# TC37X register map
File version: 1.0.0
CPU: CM4 r0p1, little endian, MPU, FPU, VTOR, 3 interrupt priority bits
Registers are 16-bit, read-write, reset 0x0 unless marked. A register's access mark holds for its fields unless they carry their own. Offsets are from the block's base; [hi:lo] are bit positions; {n}, {i} and the like mark numbered series; 'fields as' and 'values as' point back to an identical list.

## MTU — ce_mtu
Base 0xF0060000
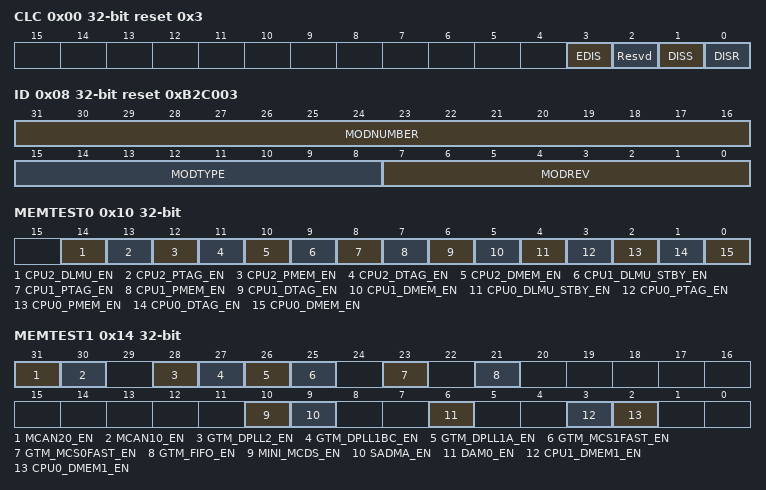
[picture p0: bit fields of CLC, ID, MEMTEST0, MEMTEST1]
0x00 CLC 32-bit reset 0x3 — Clock Control Register
  [3] EDIS — Sleep Mode Enable Control - EDIS
  [2] Resvd ro — Resvd - Resvd
  [1] DISS ro — Module Disable Status Bit - DISS
  [0] DISR — Module Disable Request Bit - DISR
0x08 ID 32-bit ro reset 0xB2C003 — Identification Register
  [31:16] MODNUMBER — Module Number - MODNUMBER
  [15:8] MODTYPE — Module Type - MODTYPE
  [7:0] MODREV — Module Revision Number - MODREV
0x10 MEMTEST0 32-bit — Memory MBIST Enable Register 0
  [14] CPU2_DLMU_EN — CPU2 DLMU memory SSH instance Enable - CPU2_DLMU_EN
  [13] CPU2_PTAG_EN — CPU2 PTAG SSH instance Enable - CPU2_PTAG_EN
  [12] CPU2_PMEM_EN — CPU2 PMEM SSH instance Enable - CPU2_PMEM_EN
  [11] CPU2_DTAG_EN — CPU2 DTAG SSH instance Enable - CPU2_DTAG_EN
  [10] CPU2_DMEM_EN — CPU2 DMEM SSH instance Enable - CPU2_DMEM_EN
  [9] CPU1_DLMU_STBY_EN — CPU1 STANDBY DLMU SSH instance Enable - CPU1_DLMU_STBY_EN
  [8] CPU1_PTAG_EN — CPU1 PTAG SSH instance Enable - CPU1_PTAG_EN
  [7] CPU1_PMEM_EN — CPU1 PMEM SSH instance Enable - CPU1_PMEM_EN
  [6] CPU1_DTAG_EN — CPU1 DTAG SSH instance Enable - CPU1_DTAG_EN
  [5] CPU1_DMEM_EN — CPU1 DMEM SSH instance Enable - CPU1_DMEM_EN
  [4] CPU0_DLMU_STBY_EN — CPU0 STANDBY DLMU SSH instance Enable - CPU0_DLMU_STBY_EN
  [3] CPU0_PTAG_EN — CPU0 PTAG SSH instance Enable - CPU0_PTAG_EN
  [2] CPU0_PMEM_EN — CPU0 PMEM SSH instance Enable - CPU0_PMEM_EN
  [1] CPU0_DTAG_EN — CPU0 DTAG SSH instance Enable - CPU0_DTAG_EN
  [0] CPU0_DMEM_EN — CPU0 DMEM SSH instance Enable - CPU0_DMEM_EN
0x14 MEMTEST1 32-bit — Memory MBIST Enable Register 1
  [31] MCAN20_EN — MCAN20 memory SSH instance Enable - MCAN20_EN
  [30] MCAN10_EN — MCAN10 memory SSH instance Enable - MCAN10_EN
  [28] GTM_DPLL2_EN — GTM DPLL2 memory SSH instance Enable - GTM_DPLL2_EN
  [27] GTM_DPLL1BC_EN — GTM DPLL1BC memory SSH instance Enable - GTM_DPLL1BC_EN
  [26] GTM_DPLL1A_EN — GTM DPLL1A memory SSH instance Enable - GTM_DPLL1A_EN
  [25] GTM_MCS1FAST_EN — GTM MCS1 FAST memory SSH instance Enable - GTM_MCS1FAST_EN
  [23] GTM_MCS0FAST_EN — GTM MCS0 FAST memory SSH instance Enable - GTM_MCS0FAST_EN
  [21] GTM_FIFO_EN — GTM FIFO memory SSH instance Enable - GTM_FIFO_EN
  [10] MINI_MCDS_EN — MINI MCDS memory SSH instance Enable - MINI_MCDS_EN
  [9] SADMA_EN — Safety DMA SSH instance Enable - SADMA_EN
  [6] DAM0_EN — DAM0 SSH instance Enable - DAM0_EN
  [3] CPU1_DMEM1_EN — CPU1 DMEM1 SSH instance Enable - CPU1_DMEM1_EN
  [2] CPU0_DMEM1_EN — CPU0 DMEM1 SSH instance Enable - CPU0_DMEM1_EN
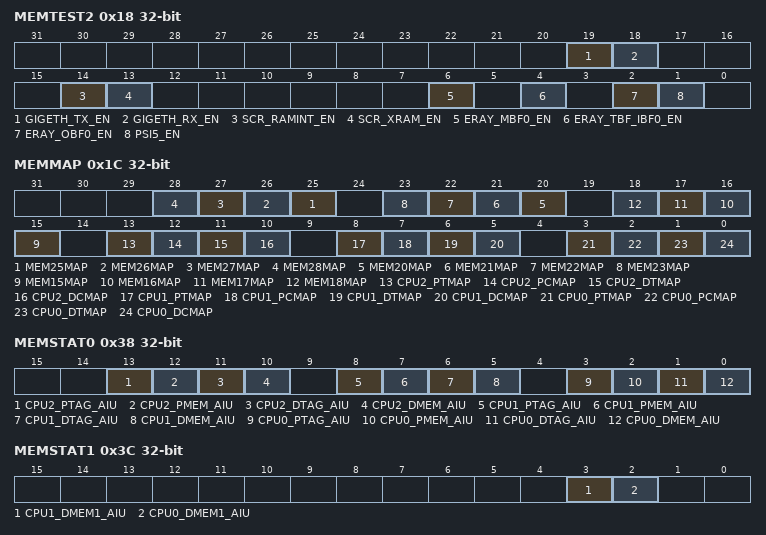
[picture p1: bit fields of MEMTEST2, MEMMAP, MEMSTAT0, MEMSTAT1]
0x18 MEMTEST2 32-bit — Memory MBIST Enable Register 2
  [19] GIGETH_TX_EN — Gigabit Ethernet TX SSH instance Enable - GIGETH_TX_EN
  [18] GIGETH_RX_EN — Gigabit Ethernet RX SSH instance Enable - GIGETH_RX_EN
  [14] SCR_RAMINT_EN — SCR Internal RAM SSH instance Enable - SCR_RAMINT_EN
  [13] SCR_XRAM_EN — SCR XRAM SSH instance Enable - SCR_XRAM_EN
  [6] ERAY_MBF0_EN — ERAY MBF0 memory SSH instance Enable - ERAY_MBF0_EN
  [4] ERAY_TBF_IBF0_EN — ERAY TBF IBF0 memory SSH instance Enable - ERAY_TBF_IBF0_EN
  [2] ERAY_OBF0_EN — ERAY OBF0 SSH instance Enable - ERAY_OBF0_EN
  [1] PSI5_EN — PSI5 memory SSH instance Enable - PSI5_EN
0x1C MEMMAP 32-bit — Memory Mapping Enable Register
  [n] MEM{n}MAP ro (n=25..28) — MEM{n} Mapping Enable - MEM{n}MAP
  [n] MEM{n}MAP ro (n=20..23) — MEM{n} Mapping Enable - MEM{n}MAP
  [n] MEM{n}MAP ro (n=15..18) — MEM{n} Mapping Enable - MEM{n}MAP
  [13] CPU2_PTMAP ro — CPU2 PTAG Mapping - CPU2_PTMAP
  [12] CPU2_PCMAP — CPU2 PCACHE Mapping - CPU2_PCMAP
  [11] CPU2_DTMAP ro — CPU2 DTAG Mapping - CPU2_DTMAP
  [10] CPU2_DCMAP — CPU2 DCache Mapping - CPU2_DCMAP
  [8] CPU1_PTMAP ro — CPU1 PTAG Mapping - CPU1_PTMAP
  [7] CPU1_PCMAP — CPU1 PCACHE Mapping - CPU1_PCMAP
  [6] CPU1_DTMAP ro — CPU1 DTAG Mapping - CPU1_DTMAP
  [5] CPU1_DCMAP — CPU1 DCache Mapping - CPU1_DCMAP
  [3] CPU0_PTMAP ro — CPU0 PTAG Mapping - CPU0_PTMAP
  [2] CPU0_PCMAP — CPU0 PCACHE Mapping - CPU0_PCMAP
  [1] CPU0_DTMAP ro — CPU0 DTAG Mapping - CPU0_DTMAP
  [0] CPU0_DCMAP — CPU0 DCache Mapping - CPU0_DCMAP
0x38 MEMSTAT0 32-bit ro — Memory Status Register 0
  [13] CPU2_PTAG_AIU — CPU2 PTAG MBIST AutoInitialize Underway - CPU2_PTAG_AIU
  [12] CPU2_PMEM_AIU — CPU2 PMEM Partial AutoInitialize of Cache Partition Underway - CPU2_PMEM_AIU
  [11] CPU2_DTAG_AIU — CPU2 DTAG MBIST AutoInitialize Underway - CPU2_DTAG_AIU
  [10] CPU2_DMEM_AIU — CPU2 DMEM Partial AutoInitialize of Cache Partition Underway - CPU2_DMEM_AIU
  [8] CPU1_PTAG_AIU — CPU1 PTAG MBIST AutoInitialize Underway - CPU1_PTAG_AIU
  [7] CPU1_PMEM_AIU — CPU1 PMEM Partial AutoInitialize of Cache Partition Underway - CPU1_PMEM_AIU
  [6] CPU1_DTAG_AIU — CPU1 DTAG MBIST AutoInitialize Underway - CPU1_DTAG_AIU
  [5] CPU1_DMEM_AIU — CPU1 DMEM Partial AutoInitialize of Cache Partition Underway - CPU1_DMEM_AIU
  [3] CPU0_PTAG_AIU — CPU0 PTAG MBIST AutoInitialize Underway - CPU0_PTAG_AIU
  [2] CPU0_PMEM_AIU — CPU0 PMEM Partial AutoInitialize of Cache Partition Underway - CPU0_PMEM_AIU
  [1] CPU0_DTAG_AIU — CPU0 DTAG MBIST AutoInitialize Underway - CPU0_DTAG_AIU
  [0] CPU0_DMEM_AIU — CPU0 DMEM Partial AutoInitialize of Cache Partition Underway - CPU0_DMEM_AIU
0x3C MEMSTAT1 32-bit ro — Memory Status Register 1
  [3] CPU1_DMEM1_AIU — CPU1 DMEM1 Partial AutoInitialize of Cache Partition Underway - CPU1_DMEM1_AIU
  [2] CPU0_DMEM1_AIU — CPU0 DMEM1 Partial AutoInitialize of Cache Partition Underway - CPU0_DMEM1_AIU
0x40 MEMSTAT2 32-bit ro — Memory Status Register 2
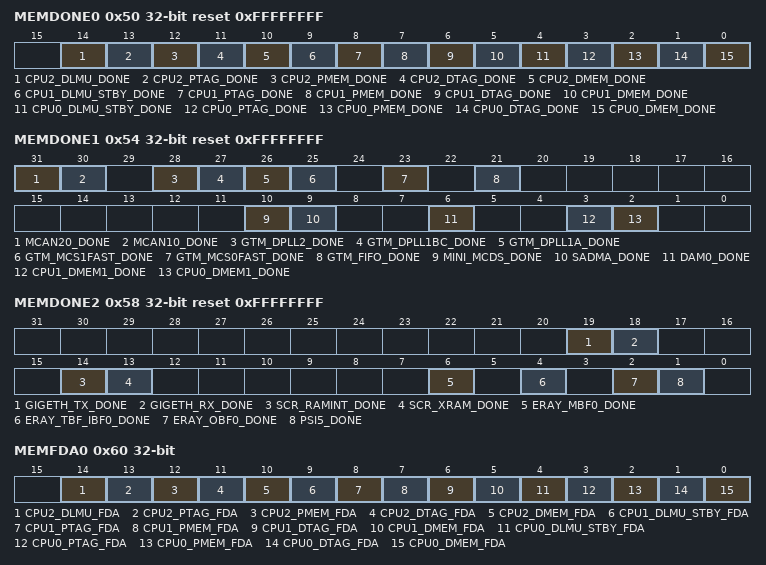
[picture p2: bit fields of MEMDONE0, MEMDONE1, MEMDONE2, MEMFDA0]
0x50 MEMDONE0 32-bit ro reset 0xFFFFFFFF — Memory Test Done Status Register 0
  [14] CPU2_DLMU_DONE — CPU2 DLMU memory Test Done Status - CPU2_DLMU_DONE
  [13] CPU2_PTAG_DONE — CPU2 PTAG Test Done Status - CPU2_PTAG_DONE
  [12] CPU2_PMEM_DONE — CPU2 PMEM Test Done Status - CPU2_PMEM_DONE
  [11] CPU2_DTAG_DONE — CPU2 DTAG Test Done Status - CPU2_DTAG_DONE
  [10] CPU2_DMEM_DONE — CPU2 DMEM Test Done Status - CPU2_DMEM_DONE
  [9] CPU1_DLMU_STBY_DONE — CPU1 STANDBY DLMU Test Done Status - CPU1_DLMU_STBY_DONE
  [8] CPU1_PTAG_DONE — CPU1 PTAG Test Done Status - CPU1_PTAG_DONE
  [7] CPU1_PMEM_DONE — CPU1 PMEM Test Done Status - CPU1_PMEM_DONE
  [6] CPU1_DTAG_DONE — CPU1 DTAG Test Done Status - CPU1_DTAG_DONE
  [5] CPU1_DMEM_DONE — CPU1 DMEM Test Done Status - CPU1_DMEM_DONE
  [4] CPU0_DLMU_STBY_DONE — CPU0 STANDBY DLMU Test Done Status - CPU0_DLMU_STBY_DONE
  [3] CPU0_PTAG_DONE — CPU0 PTAG Test Done Status - CPU0_PTAG_DONE
  [2] CPU0_PMEM_DONE — CPU0 PMEM Test Done Status - CPU0_PMEM_DONE
  [1] CPU0_DTAG_DONE — CPU0 DTAG Test Done Status - CPU0_DTAG_DONE
  [0] CPU0_DMEM_DONE — CPU0 DMEM Test Done Status - CPU0_DMEM_DONE
0x54 MEMDONE1 32-bit ro reset 0xFFFFFFFF — Memory Test Done Status Register 1
  [31] MCAN20_DONE — MCAN20 memory Test Done Status - MCAN20_DONE
  [30] MCAN10_DONE — MCAN10 memory Test Done Status - MCAN10_DONE
  [28] GTM_DPLL2_DONE — GTM DPLL2 memory Test Done Status - GTM_DPLL2_DONE
  [27] GTM_DPLL1BC_DONE — GTM DPLL1BC memory Test Done Status - GTM_DPLL1BC_DONE
  [26] GTM_DPLL1A_DONE — GTM DPLL1A memory Test Done Status - GTM_DPLL1A_DONE
  [25] GTM_MCS1FAST_DONE — GTM MCS1 FAST memory Test Done Status - GTM_MCS1FAST_DONE
  [23] GTM_MCS0FAST_DONE — GTM MCS0 FAST memory Test Done Status - GTM_MCS0FAST_DONE
  [21] GTM_FIFO_DONE — GTM FIFO memory Test Done Status - GTM_FIFO_DONE
  [10] MINI_MCDS_DONE — MINI MCDS memory Test Done Status - MINI_MCDS_DONE
  [9] SADMA_DONE — Safety DMA Test Done Status - SADMA_DONE
  [6] DAM0_DONE — DAM0 Test Done Status - DAM0_DONE
  [3] CPU1_DMEM1_DONE — CPU1 DMEM1 Test Done Status - CPU1_DMEM1_DONE
  [2] CPU0_DMEM1_DONE — CPU0 DMEM1 Test Done Status - CPU0_DMEM1_DONE
0x58 MEMDONE2 32-bit ro reset 0xFFFFFFFF — Memory Test Done Status Register 2
  [19] GIGETH_TX_DONE — Gigabit Ethernet TX memoryTest Done Status - GIGETH_TX_DONE
  [18] GIGETH_RX_DONE — Gigabit Ethernet RX memoryTest Done Status - GIGETH_RX_DONE
  [14] SCR_RAMINT_DONE — SCR Internal RAM Test Done Status - SCR_RAMINT_DONE
  [13] SCR_XRAM_DONE — SCR XRAM Test Done Status - SCR_XRAM_DONE
  [6] ERAY_MBF0_DONE — ERAY MBF0 memory Test Done Status - ERAY_MBF0_DONE
  [4] ERAY_TBF_IBF0_DONE — ERAY TBF IBF0 memory Test Done Status - ERAY_TBF_IBF0_DONE
  [2] ERAY_OBF0_DONE — ERAY OBF0 Test Done Status - ERAY_OBF0_DONE
  [1] PSI5_DONE — PSI5 memory Test Done Status - PSI5_DONE
0x60 MEMFDA0 32-bit ro — Memory Test FDA Status Register 0
  [14] CPU2_DLMU_FDA — CPU2 DLMU memory Test FDA Status - CPU2_DLMU_FDA
  [13] CPU2_PTAG_FDA — CPU2 PTAG Test FDA Status - CPU2_PTAG_FDA
  [12] CPU2_PMEM_FDA — CPU2 PMEM Test FDA Status - CPU2_PMEM_FDA
  [11] CPU2_DTAG_FDA — CPU2 DTAG Test FDA Status - CPU2_DTAG_FDA
  [10] CPU2_DMEM_FDA — CPU2 DMEM Test FDA Status - CPU2_DMEM_FDA
  [9] CPU1_DLMU_STBY_FDA — CPU1 STANDBY DLMU Test FDA Status - CPU1_DLMU_STBY_FDA
  [8] CPU1_PTAG_FDA — CPU1 PTAG Test FDA Status - CPU1_PTAG_FDA
  [7] CPU1_PMEM_FDA — CPU1 PMEM Test FDA Status - CPU1_PMEM_FDA
  [6] CPU1_DTAG_FDA — CPU1 DTAG Test FDA Status - CPU1_DTAG_FDA
  [5] CPU1_DMEM_FDA — CPU1 DMEM Test FDA Status - CPU1_DMEM_FDA
  [4] CPU0_DLMU_STBY_FDA — CPU0 STANDBY DLMU Test FDA Status - CPU0_DLMU_STBY_FDA
  [3] CPU0_PTAG_FDA — CPU0 PTAG Test FDA Status - CPU0_PTAG_FDA
  [2] CPU0_PMEM_FDA — CPU0 PMEM Test FDA Status - CPU0_PMEM_FDA
  [1] CPU0_DTAG_FDA — CPU0 DTAG Test FDA Status - CPU0_DTAG_FDA
  [0] CPU0_DMEM_FDA — CPU0 DMEM Test FDA Status - CPU0_DMEM_FDA
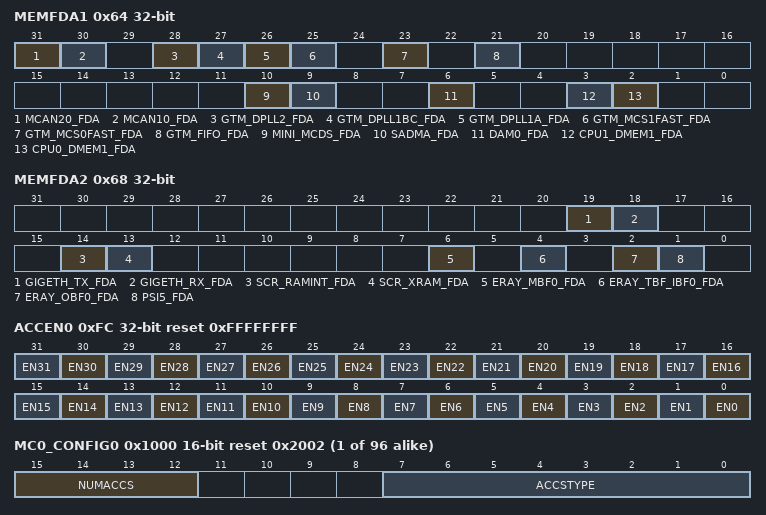
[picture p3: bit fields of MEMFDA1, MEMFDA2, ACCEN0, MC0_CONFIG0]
0x64 MEMFDA1 32-bit ro — Memory Test FDA Status Register 1
  [31] MCAN20_FDA — MCAN20 memory Test FDA Status - MCAN20_FDA
  [30] MCAN10_FDA — MCAN10 memory Test FDA Status - MCAN10_FDA
  [28] GTM_DPLL2_FDA — GTM DPLL2 memory Test FDA Status - GTM_DPLL2_FDA
  [27] GTM_DPLL1BC_FDA — GTM DPLL1BC memory Test FDA Status - GTM_DPLL1BC_FDA
  [26] GTM_DPLL1A_FDA — GTM DPLL1A memory Test FDA Status - GTM_DPLL1A_FDA
  [25] GTM_MCS1FAST_FDA — GTM MCS1 FAST memory Test FDA Status - GTM_MCS1FAST_FDA
  [23] GTM_MCS0FAST_FDA — GTM MCS0 FAST memory Test FDA Status - GTM_MCS0FAST_FDA
  [21] GTM_FIFO_FDA — GTM FIFO memory Test FDA Status - GTM_FIFO_FDA
  [10] MINI_MCDS_FDA — MINI MCDS memory Test FDA Status - MINI_MCDS_FDA
  [9] SADMA_FDA — Safety DMA Test FDA Status - SADMA_FDA
  [6] DAM0_FDA — DAM0 Test FDA Status - DAM0_FDA
  [3] CPU1_DMEM1_FDA — CPU1 DMEM1 Test FDA Status - CPU1_DMEM1_FDA
  [2] CPU0_DMEM1_FDA — CPU0 DMEM1 Test FDA Status - CPU0_DMEM1_FDA
0x68 MEMFDA2 32-bit ro — Memory Test FDA Status Register 2
  [19] GIGETH_TX_FDA — Gigabit Ethernet TX SSH memory Test FDA Status - GIGETH_TX_FDA
  [18] GIGETH_RX_FDA — Gigabit Ethernet RX memory Test FDA Status - GIGETH_RX_FDA
  [14] SCR_RAMINT_FDA — SCR Internal RAM Test FDA Status - SCR_RAMINT_FDA
  [13] SCR_XRAM_FDA — SCR XRAM Test FDA Status - SCR_XRAM_FDA
  [6] ERAY_MBF0_FDA — ERAY MBF0 memory Test FDA Status - ERAY_MBF0_FDA
  [4] ERAY_TBF_IBF0_FDA — ERAY TBF IBF0 memory Test FDA Status - ERAY_TBF_IBF0_FDA
  [2] ERAY_OBF0_FDA — ERAY OBF0 Test FDA Status - ERAY_OBF0_FDA
  [1] PSI5_FDA — PSI5 memory Test FDA Status - PSI5_FDA
0xF8 ACCEN1 32-bit ro — Access Enable Register 1
0xFC ACCEN0 32-bit reset 0xFFFFFFFF — Access Enable Register 0
  [n] EN{n} (n=0..31) — Access Enable for Master TAG ID {n} - EN{n}
{0x1000+0x100*i} MC{i}_CONFIG0 reset 0x2002 (i=0..95) — Configuration Registers
  [15:12] NUMACCS — Number of accesses per address - NUMACCS
  [7:0] ACCSTYPE — Access type - ACCSTYPE
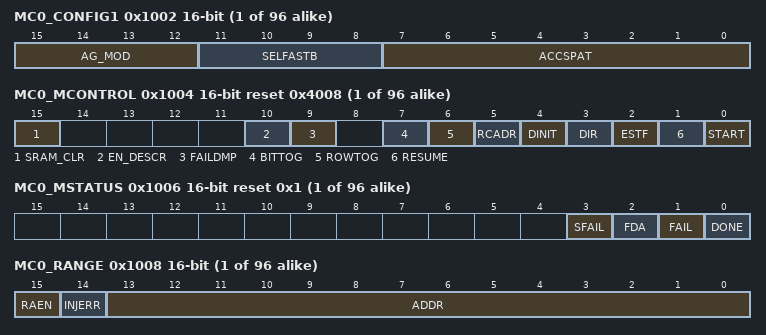
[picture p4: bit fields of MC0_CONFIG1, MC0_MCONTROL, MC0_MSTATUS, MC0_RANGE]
{0x1002+0x100*i} MC{i}_CONFIG1 (i=0..95) — Configuration Register 1
  [15:12] AG_MOD — Address Generator Mode - AG_MOD
  [11:8] SELFASTB — Select Fast Bit - SELFASTB
  [7:0] ACCSPAT — Access pattern - ACCSPAT
{0x1004+0x100*i} MC{i}_MCONTROL reset 0x4008 (i=0..95) — MBIST Control Register
  [15] SRAM_CLR — Clear the SRAM - SRAM_CLR
  [10] EN_DESCR — Enable Descrambling
  [9] FAILDMP — Fail bitmap dump - FAILDMP
  [7] BITTOG — Bit toggling - BITTOG
  [6] ROWTOG — Row toggling - ROWTOG
  [5] RCADR — Fast Row / Fast Column Addressing Scheme Select - RCADR
  [4] DINIT — Data Initialization Enable - DINIT
  [3] DIR — Direction Select - DIR
  [2] ESTF — Enable Sticky Fail Bit - ESTF
  [1] RESUME — Resume failed test - RESUME
  [0] START — START - START
{0x1006+0x100*i} MC{i}_MSTATUS ro reset 0x1 (i=0..95) — Status Register
  [3] SFAIL — Sticky Fail Bit - SFAIL
  [2] FDA — Fail Dump Available - FDA
  [1] FAIL — FAIL - FAIL
  [0] DONE — DONE - DONE
{0x1008+0x100*i} MC{i}_RANGE reset not defined (i=0..95) — Range Register, single address mode
  [15] RAEN — Range Enable - RAEN
  [14] INJERR — Inject Error - INJERR
  [13:0] ADDR — Address - ADDR
{0x100C+0x100*i} MC{i}_REVID ro reset 0x610 (i=0..95) — Revision ID Register
  [15:0] REV_ID — Revision Identifier - REV_ID
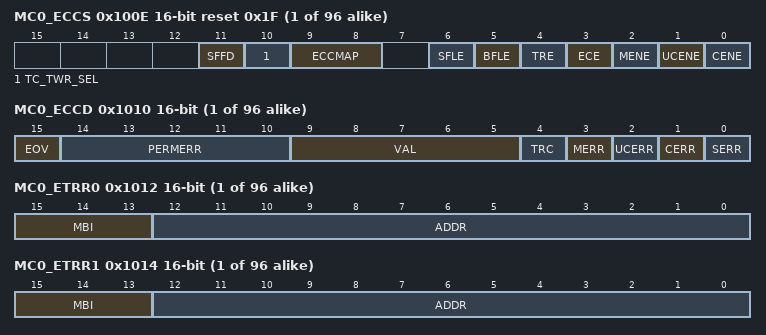
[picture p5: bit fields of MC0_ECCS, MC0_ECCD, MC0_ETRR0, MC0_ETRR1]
{0x100E+0x100*i} MC{i}_ECCS reset 0x1F (i=0..95) — ECC Safety Register
  [11] SFFD — Safety Flip-Flop Diagnostics - SFFD
  [10] TC_TWR_SEL — TriCore Tower Select - TC_TWR_SEL
  [9:8] ECCMAP — ECC Bit Mapping Mode - ECCMAP
  [6] SFLE — Signature Bit Flip Enables - SFLE
  [5] BFLE — Bit Flip Enable - BFLE
  [4] TRE — Tracking Enable - TRE
  [3] ECE — Error Correction Enable - ECE
  [2] MENE — Miscellaneous Alarm Notification Enable: MENE
  [1] UCENE — Uncorrectable Error Affecting SRAM / SSH Operation: Alarm Notification Enable - UENE
  [0] CENE — ECC Correction Event Alarm Notification Enable - CENE
{0x1010+0x100*i} MC{i}_ECCD (i=0..95) — Memory ECC Detection Register
  [15] EOV ro — Error Overflow - EOV
  [14:10] PERMERR — Permanent Error in ETRR Entry - PERMERR
  [9:5] VAL ro — Valid Bits - VAL
  [4] TRC wo — Tracking Clear - TRC
  [3] MERR — Miscellaneous Error Alarm Occured - MERR
  [2] UCERR — Uncorrectable Error Alarm Occured - UCERR
  [1] CERR — CE alarm occured - CERR
  [0] SERR — Error Detected - SERR
{0x1012+0x100*i} MC{i}_ETRR0 ro (i=0..95) — Error Tracking Register 0
  [15:13] MBI — Memory Block Index of Error(i) - MBI
  [12:0] ADDR — Address of Error(i) - ADDR
{0x1014+0x100*i} MC{i}_ETRR1 ro (i=0..95) — Error Tracking Register 1
  fields as MC0_ETRR0
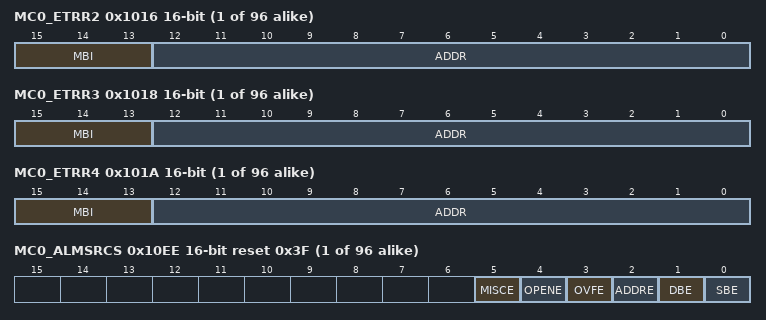
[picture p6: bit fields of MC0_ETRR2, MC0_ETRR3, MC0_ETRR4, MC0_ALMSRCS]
{0x1016+0x100*i} MC{i}_ETRR2 ro (i=0..95) — Error Tracking Register 2
  fields as MC0_ETRR0
{0x1018+0x100*i} MC{i}_ETRR3 ro (i=0..95) — Error Tracking Register 3
  fields as MC0_ETRR0
{0x101A+0x100*i} MC{i}_ETRR4 ro (i=0..95) — Error Tracking Register 4
  fields as MC0_ETRR0
{0x1060+0x100*i} MC{i}_RDBFL0 (i=0..95) — Read Data and Bit Flip Register 0
  [15:0] WDATA — Word Data - WDATA
{0x1062+0x100*i} MC{i}_RDBFL1 (i=0..95) — Read Data and Bit Flip Register 1
  [15:0] WDATA — Word Data - WDATA
{0x1064+0x100*i} MC{i}_RDBFL2 (i=0..95) — Read Data and Bit Flip Register 2
  [15:0] WDATA — Word Data - WDATA
{0x1066+0x100*i} MC{i}_RDBFL3 (i=0..95) — Read Data and Bit Flip Register 3
  [15:0] WDATA — Word Data - WDATA
{0x1068+0x100*i} MC{i}_RDBFL4 (i=0..95) — Read Data and Bit Flip Register 4
  [15:0] WDATA — Word Data - WDATA
{0x106A+0x100*i} MC{i}_RDBFL5 (i=0..95) — Read Data and Bit Flip Register 5
  [15:0] WDATA — Word Data - WDATA
{0x106C+0x100*i} MC{i}_RDBFL6 (i=0..95) — Read Data and Bit Flip Register 6
  [15:0] WDATA — Word Data - WDATA
{0x106E+0x100*i} MC{i}_RDBFL7 (i=0..95) — Read Data and Bit Flip Register 7
  [15:0] WDATA — Word Data - WDATA
{0x1070+0x100*i} MC{i}_RDBFL8 (i=0..95) — Read Data and Bit Flip Register 8
  [15:0] WDATA — Word Data - WDATA
{0x1072+0x100*i} MC{i}_RDBFL9 (i=0..95) — Read Data and Bit Flip Register 9
  [15:0] WDATA — Word Data - WDATA
{0x1074+0x100*i} MC{i}_RDBFL10 (i=0..95) — Read Data and Bit Flip Register 10
  [15:0] WDATA — Word Data - WDATA
{0x1076+0x100*i} MC{i}_RDBFL11 (i=0..95) — Read Data and Bit Flip Register 11
  [15:0] WDATA — Word Data - WDATA
{0x1078+0x100*i} MC{i}_RDBFL12 (i=0..95) — Read Data and Bit Flip Register 12
  [15:0] WDATA — Word Data - WDATA
{0x107A+0x100*i} MC{i}_RDBFL13 (i=0..95) — Read Data and Bit Flip Register 13
  [15:0] WDATA — Word Data - WDATA
{0x107C+0x100*i} MC{i}_RDBFL14 (i=0..95) — Read Data and Bit Flip Register 14
  [15:0] WDATA — Word Data - WDATA
{0x107E+0x100*i} MC{i}_RDBFL15 (i=0..95) — Read Data and Bit Flip Register 15
  [15:0] WDATA — Word Data - WDATA
{0x1080+0x100*i} MC{i}_RDBFL16 (i=0..95) — Read Data and Bit Flip Register 16
  [15:0] WDATA — Word Data - WDATA
{0x1082+0x100*i} MC{i}_RDBFL17 (i=0..95) — Read Data and Bit Flip Register 17
  [15:0] WDATA — Word Data - WDATA
{0x1084+0x100*i} MC{i}_RDBFL18 (i=0..95) — Read Data and Bit Flip Register 18
  [15:0] WDATA — Word Data - WDATA
{0x1086+0x100*i} MC{i}_RDBFL19 (i=0..95) — Read Data and Bit Flip Register 19
  [15:0] WDATA — Word Data - WDATA
{0x1088+0x100*i} MC{i}_RDBFL20 (i=0..95) — Read Data and Bit Flip Register 20
  [15:0] WDATA — Word Data - WDATA
{0x108A+0x100*i} MC{i}_RDBFL21 (i=0..95) — Read Data and Bit Flip Register 21
  [15:0] WDATA — Word Data - WDATA
{0x108C+0x100*i} MC{i}_RDBFL22 (i=0..95) — Read Data and Bit Flip Register 22
  [15:0] WDATA — Word Data - WDATA
{0x108E+0x100*i} MC{i}_RDBFL23 (i=0..95) — Read Data and Bit Flip Register 23
  [15:0] WDATA — Word Data - WDATA
{0x1090+0x100*i} MC{i}_RDBFL24 (i=0..95) — Read Data and Bit Flip Register 24
  [15:0] WDATA — Word Data - WDATA
{0x1092+0x100*i} MC{i}_RDBFL25 (i=0..95) — Read Data and Bit Flip Register 25
  [15:0] WDATA — Word Data - WDATA
{0x1094+0x100*i} MC{i}_RDBFL26 (i=0..95) — Read Data and Bit Flip Register 26
  [15:0] WDATA — Word Data - WDATA
{0x1096+0x100*i} MC{i}_RDBFL27 (i=0..95) — Read Data and Bit Flip Register 27
  [15:0] WDATA — Word Data - WDATA
{0x1098+0x100*i} MC{i}_RDBFL28 (i=0..95) — Read Data and Bit Flip Register 28
  [15:0] WDATA — Word Data - WDATA
{0x109A+0x100*i} MC{i}_RDBFL29 (i=0..95) — Read Data and Bit Flip Register 29
  [15:0] WDATA — Word Data - WDATA
{0x109C+0x100*i} MC{i}_RDBFL30 (i=0..95) — Read Data and Bit Flip Register 30
  [15:0] WDATA — Word Data - WDATA
{0x109E+0x100*i} MC{i}_RDBFL31 (i=0..95) — Read Data and Bit Flip Register 31
  [15:0] WDATA — Word Data - WDATA
{0x10A0+0x100*i} MC{i}_RDBFL32 (i=0..95) — Read Data and Bit Flip Register 32
  [15:0] WDATA — Word Data - WDATA
{0x10A2+0x100*i} MC{i}_RDBFL33 (i=0..95) — Read Data and Bit Flip Register 33
  [15:0] WDATA — Word Data - WDATA
{0x10A4+0x100*i} MC{i}_RDBFL34 (i=0..95) — Read Data and Bit Flip Register 34
  [15:0] WDATA — Word Data - WDATA
{0x10A6+0x100*i} MC{i}_RDBFL35 (i=0..95) — Read Data and Bit Flip Register 35
  [15:0] WDATA — Word Data - WDATA
{0x10A8+0x100*i} MC{i}_RDBFL36 (i=0..95) — Read Data and Bit Flip Register 36
  [15:0] WDATA — Word Data - WDATA
{0x10AA+0x100*i} MC{i}_RDBFL37 (i=0..95) — Read Data and Bit Flip Register 37
  [15:0] WDATA — Word Data - WDATA
{0x10AC+0x100*i} MC{i}_RDBFL38 (i=0..95) — Read Data and Bit Flip Register 38
  [15:0] WDATA — Word Data - WDATA
{0x10AE+0x100*i} MC{i}_RDBFL39 (i=0..95) — Read Data and Bit Flip Register 39
  [15:0] WDATA — Word Data - WDATA
{0x10B0+0x100*i} MC{i}_RDBFL40 (i=0..95) — Read Data and Bit Flip Register 40
  [15:0] WDATA — Word Data - WDATA
{0x10B2+0x100*i} MC{i}_RDBFL41 (i=0..95) — Read Data and Bit Flip Register 41
  [15:0] WDATA — Word Data - WDATA
{0x10B4+0x100*i} MC{i}_RDBFL42 (i=0..95) — Read Data and Bit Flip Register 42
  [15:0] WDATA — Word Data - WDATA
{0x10B6+0x100*i} MC{i}_RDBFL43 (i=0..95) — Read Data and Bit Flip Register 43
  [15:0] WDATA — Word Data - WDATA
{0x10B8+0x100*i} MC{i}_RDBFL44 (i=0..95) — Read Data and Bit Flip Register 44
  [15:0] WDATA — Word Data - WDATA
{0x10BA+0x100*i} MC{i}_RDBFL45 (i=0..95) — Read Data and Bit Flip Register 45
  [15:0] WDATA — Word Data - WDATA
{0x10BC+0x100*i} MC{i}_RDBFL46 (i=0..95) — Read Data and Bit Flip Register 46
  [15:0] WDATA — Word Data - WDATA
{0x10BE+0x100*i} MC{i}_RDBFL47 (i=0..95) — Read Data and Bit Flip Register 47
  [15:0] WDATA — Word Data - WDATA
{0x10C0+0x100*i} MC{i}_RDBFL48 (i=0..95) — Read Data and Bit Flip Register 48
  [15:0] WDATA — Word Data - WDATA
{0x10C2+0x100*i} MC{i}_RDBFL49 (i=0..95) — Read Data and Bit Flip Register 49
  [15:0] WDATA — Word Data - WDATA
{0x10C4+0x100*i} MC{i}_RDBFL50 (i=0..95) — Read Data and Bit Flip Register 50
  [15:0] WDATA — Word Data - WDATA
{0x10C6+0x100*i} MC{i}_RDBFL51 (i=0..95) — Read Data and Bit Flip Register 51
  [15:0] WDATA — Word Data - WDATA
{0x10C8+0x100*i} MC{i}_RDBFL52 (i=0..95) — Read Data and Bit Flip Register 52
  [15:0] WDATA — Word Data - WDATA
{0x10CA+0x100*i} MC{i}_RDBFL53 (i=0..95) — Read Data and Bit Flip Register 53
  [15:0] WDATA — Word Data - WDATA
{0x10CC+0x100*i} MC{i}_RDBFL54 (i=0..95) — Read Data and Bit Flip Register 54
  [15:0] WDATA — Word Data - WDATA
{0x10CE+0x100*i} MC{i}_RDBFL55 (i=0..95) — Read Data and Bit Flip Register 55
  [15:0] WDATA — Word Data - WDATA
{0x10D0+0x100*i} MC{i}_RDBFL56 (i=0..95) — Read Data and Bit Flip Register 56
  [15:0] WDATA — Word Data - WDATA
{0x10D2+0x100*i} MC{i}_RDBFL57 (i=0..95) — Read Data and Bit Flip Register 57
  [15:0] WDATA — Word Data - WDATA
{0x10D4+0x100*i} MC{i}_RDBFL58 (i=0..95) — Read Data and Bit Flip Register 58
  [15:0] WDATA — Word Data - WDATA
{0x10D6+0x100*i} MC{i}_RDBFL59 (i=0..95) — Read Data and Bit Flip Register 59
  [15:0] WDATA — Word Data - WDATA
{0x10D8+0x100*i} MC{i}_RDBFL60 (i=0..95) — Read Data and Bit Flip Register 60
  [15:0] WDATA — Word Data - WDATA
{0x10DA+0x100*i} MC{i}_RDBFL61 (i=0..95) — Read Data and Bit Flip Register 61
  [15:0] WDATA — Word Data - WDATA
{0x10DC+0x100*i} MC{i}_RDBFL62 (i=0..95) — Read Data and Bit Flip Register 62
  [15:0] WDATA — Word Data - WDATA
{0x10DE+0x100*i} MC{i}_RDBFL63 (i=0..95) — Read Data and Bit Flip Register 63
  [15:0] WDATA — Word Data - WDATA
{0x10E0+0x100*i} MC{i}_RDBFL64 (i=0..95) — Read Data and Bit Flip Register 64
  [15:0] WDATA — Word Data - WDATA
{0x10E2+0x100*i} MC{i}_RDBFL65 (i=0..95) — Read Data and Bit Flip Register 65
  [15:0] WDATA — Word Data - WDATA
{0x10E4+0x100*i} MC{i}_RDBFL66 (i=0..95) — Read Data and Bit Flip Register 66
  [15:0] WDATA — Word Data - WDATA
{0x10EE+0x100*i} MC{i}_ALMSRCS reset 0x3F (i=0..95) — Alarm Sources Configuration Register
  [5] MISCE — SSH Misc. Errors Notification Enable - MISCE
  [4] OPENE — SSH Operational Error Notification Enable - OPENE
  [3] OVFE — ETRR Overflow notification enable- OVFE
  [2] ADDRE — Address Error Notification Enable - ADDRE
  [1] DBE — Double Bit Error Notification and Tracking Enable - DBE
  [0] SBE — Single Bit Error Notification & Tracking Enable - SBE
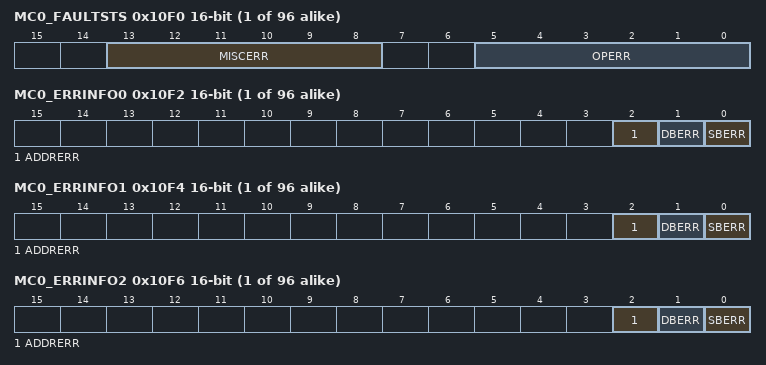
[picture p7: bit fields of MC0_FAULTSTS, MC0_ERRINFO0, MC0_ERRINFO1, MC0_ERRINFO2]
{0x10F0+0x100*i} MC{i}_FAULTSTS (i=0..95) — SSH Safety Faults Status Register
  [13:8] MISCERR — SSH Miscellaneous Error Status- MISCERR
  [5:0] OPERR — SSH Critical Operation Error Occured - OPERR
{0x10F2+0x100*i} MC{i}_ERRINFO0 ro (i=0..95) — Error Information Register 0
  [2] ADDRERR — Address Fault Detected - ADDRERR
  [1] DBERR — Double Bit Error Detected - DBERR
  [0] SBERR — Single Bit Error Detected - SBERR
{0x10F4+0x100*i} MC{i}_ERRINFO1 ro (i=0..95) — Error Information Register 1
  fields as MC0_ERRINFO0
{0x10F6+0x100*i} MC{i}_ERRINFO2 ro (i=0..95) — Error Information Register 2
  fields as MC0_ERRINFO0
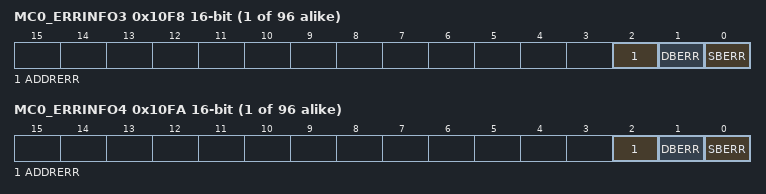
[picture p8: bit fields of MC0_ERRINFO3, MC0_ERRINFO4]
{0x10F8+0x100*i} MC{i}_ERRINFO3 ro (i=0..95) — Error Information Register 3
  fields as MC0_ERRINFO0
{0x10FA+0x100*i} MC{i}_ERRINFO4 ro (i=0..95) — Error Information Register 4
  fields as MC0_ERRINFO0
